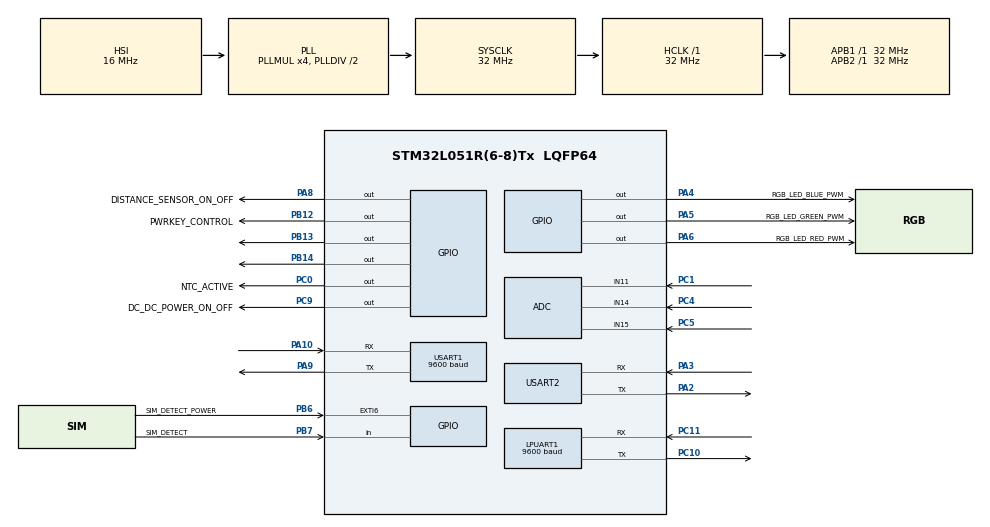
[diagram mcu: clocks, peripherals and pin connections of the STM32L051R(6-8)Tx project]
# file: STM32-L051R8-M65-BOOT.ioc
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ADC.ContinuousConvMode=ENABLE
ADC.DMAContinuousRequests=ENABLE
ADC.Overrun=ADC_OVR_DATA_OVERWRITTEN
ADC.SamplingTime=ADC_SAMPLETIME_79CYCLES_5
Dma.ADC.0.Direction=DMA_PERIPH_TO_MEMORY
Dma.ADC.0.Instance=DMA1_Channel1
Dma.ADC.0.MemDataAlignment=DMA_MDATAALIGN_HALFWORD
Dma.ADC.0.MemInc=DMA_MINC_ENABLE
Dma.ADC.0.Mode=DMA_CIRCULAR
Dma.ADC.0.PeriphDataAlignment=DMA_PDATAALIGN_HALFWORD
Dma.ADC.0.PeriphInc=DMA_PINC_DISABLE
Dma.ADC.0.Priority=DMA_PRIORITY_LOW
Dma.Request0=ADC
LPUART1.BaudRate=9600
LPUART1.WordLength=UART_WORDLENGTH_8B
Mcu.Family=STM32L0
Mcu.Name=STM32L051R(6-8)Tx
Mcu.Package=LQFP64
NVIC.ADC1_COMP_IRQn=true\:1\:0\:true\:false\:true\:true\:true\:true
NVIC.DMA1_Channel1_IRQn=true\:1\:0\:true\:false\:true\:false\:true\:true
NVIC.RCC_IRQn=true\:0\:0\:false\:false\:true\:true\:false\:true
NVIC.USART1_IRQn=true\:0\:0\:false\:false\:true\:true\:true\:true
NVIC.USART2_IRQn=true\:0\:0\:false\:false\:true\:true\:true\:true
PA10.Mode=Asynchronous
PA10.Signal=USART1_RX
PA13.Mode=Serial_Wire
PA13.Signal=SYS_SWDIO
PA14.Mode=Serial_Wire
PA14.Signal=SYS_SWCLK
PA2.Mode=Asynchronous
PA2.Signal=USART2_TX
PA3.Mode=Asynchronous
PA3.Signal=USART2_RX
PA4.GPIO_Label=RGB_LED_BLUE_PWM
PA4.GPIO_Speed=GPIO_SPEED_FREQ_VERY_HIGH
PA4.Signal=GPIO_Output
PA5.GPIO_Label=RGB_LED_GREEN_PWM
PA5.GPIO_Speed=GPIO_SPEED_FREQ_VERY_HIGH
PA5.Signal=GPIO_Output
PA6.GPIO_Label=RGB_LED_RED_PWM
PA6.GPIO_Speed=GPIO_SPEED_FREQ_VERY_HIGH
PA6.Signal=GPIO_Output
PA8.GPIO_Label=DISTANCE_SENSOR_ON_OFF
PA8.Signal=GPIO_Output
PA9.Mode=Asynchronous
PA9.Signal=USART1_TX
PB12.GPIO_Label=PWRKEY_CONTROL
PB12.Signal=GPIO_Output
PB13.Signal=GPIO_Output
PB14.Signal=GPIO_Output
PB6.GPIO_Label=SIM_DETECT_POWER
PB6.Signal=GPXTI6
PB7.GPIO_Label=SIM_DETECT
PB7.Signal=GPIO_Input
PC0.GPIO_Label=NTC_ACTIVE
PC0.Signal=GPIO_Output
PC1.Mode=IN11
PC1.Signal=ADC_IN11
PC10.Mode=Asynchronous
PC10.Signal=LPUART1_TX
PC11.Mode=Asynchronous
PC11.Signal=LPUART1_RX
PC14-OSC32_IN.Mode=LSE-External-Oscillator
PC14-OSC32_IN.Signal=RCC_OSC32_IN
PC15-OSC32_OUT.Mode=LSE-External-Oscillator
PC15-OSC32_OUT.Signal=RCC_OSC32_OUT
PC4.Mode=IN14
PC4.Signal=ADC_IN14
PC5.Mode=IN15
PC5.Signal=ADC_IN15
PC9.GPIO_Label=DC_DC_POWER_ON_OFF
PC9.Signal=GPIO_Output
PH0-OSC_IN.Mode=HSE-External-Oscillator
PH0-OSC_IN.Signal=RCC_OSC_IN
PH1-OSC_OUT.Mode=HSE-External-Oscillator
PH1-OSC_OUT.Signal=RCC_OSC_OUT
ProjectManager.HeapSize=0x200
ProjectManager.StackSize=0x400
ProjectManager.TargetToolchain=EWARM V7
RCC.AHBFreq_Value=32000000
RCC.APB1Freq_Value=32000000
RCC.APB1TimFreq_Value=32000000
RCC.APB2Freq_Value=32000000
RCC.APB2TimFreq_Value=32000000
RCC.HCLKFreq_Value=32000000
RCC.HSE_VALUE=8000000
RCC.HSI16_VALUE=16000000
RCC.HSI_VALUE=16000000
RCC.MSI_VALUE=2097000
RCC.PLLMUL=RCC_PLLMUL_4
RCC.SYSCLKFreq_VALUE=32000000
RCC.SYSCLKSource=RCC_SYSCLKSOURCE_PLLCLK
RCC.VCOOutputFreq_Value=64000000
RTC.Date=21
RTC.Month=RTC_MONTH_AUGUST
RTC.Year=23
USART1.BaudRate=9600
USART1.VirtualMode-Asynchronous=VM_ASYNC
USART2.VirtualMode-Asynchronous=VM_ASYNC
VP_ADC_Vref_Input.Mode=IN-Vrefint
VP_RTC_VS_RTC_Activate.Mode=RTC_Enabled
VP_RTC_VS_RTC_Calendar.Mode=RTC_Calendar
board=custom

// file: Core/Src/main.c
/* USER CODE BEGIN Header */
/**
 ******************************************************************************
 * @file           : main.c
 * @brief          : Main program body
 ******************************************************************************
 * @attention
 *
 * Copyright (c) 2023 STMicroelectronics.
 * All rights reserved.
 *
 * This software is licensed under terms that can be found in the LICENSE file
 * in the root directory of this software component.
 * If no LICENSE file comes with this software, it is provided AS-IS.
 *
 ******************************************************************************
 */
/* USER CODE END Header */
#include "main.h"
#include "adc.h"
#include "dma.h"
#include "usart.h"
#include "rtc.h"
#include "gpio.h"

/* USER CODE BEGIN Includes */
#include "usr_general.h"

/* USER CODE END Includes */

/* USER CODE BEGIN PV */
_io S_FIRST_INITIAL_PARAMETERS m_sFirstInitialParameter = {
    .pPowerPort          =  GPIOC,
    .pPowerKeyPort       =  GPIOB,

    .dcPowerOnOffPin     =  GPIO_PIN_9,
    .powerKeyControlPin  =  GPIO_PIN_12,

    .pLogUart            =  &hlpuart1,
};
/* USER CODE END PV */

void SystemClock_Config(void);

int main(void)
{

  /* MCU Configuration--------------------------------------------------------*/

  /* Reset of all peripherals, Initializes the Flash interface and the Systick. */
  HAL_Init();

  /* Configure the system clock */
  SystemClock_Config();

  /* Initialize all configured peripherals */
  MX_GPIO_Init();
  MX_DMA_Init();
  MX_USART1_UART_Init();
  MX_RTC_Init();
  MX_LPUART1_UART_Init();
  MX_USART2_UART_Init();
  MX_ADC_Init();
  /* USER CODE BEGIN 2 */
  UsrSystemInitial(&m_sFirstInitialParameter);
  /* USER CODE END 2 */

  /* Infinite loop */
  while (1)
  {

    /* USER CODE BEGIN 3 */
    UsrSystemGeneral();
  }
  /* USER CODE END 3 */
}

void SystemClock_Config(void)
{
  RCC_OscInitTypeDef RCC_OscInitStruct = {0};
  RCC_ClkInitTypeDef RCC_ClkInitStruct = {0};
  RCC_PeriphCLKInitTypeDef PeriphClkInit = {0};

  /** Configure the main internal regulator output voltage
  */
  __HAL_PWR_VOLTAGESCALING_CONFIG(PWR_REGULATOR_VOLTAGE_SCALE1);

  /** Initializes the RCC Oscillators according to the specified parameters
  * in the RCC_OscInitTypeDef structure.
  */
  RCC_OscInitStruct.OscillatorType = RCC_OSCILLATORTYPE_HSI|RCC_OSCILLATORTYPE_LSI;
  RCC_OscInitStruct.HSIState = RCC_HSI_ON;
  RCC_OscInitStruct.HSICalibrationValue = RCC_HSICALIBRATION_DEFAULT;
  RCC_OscInitStruct.LSIState = RCC_LSI_ON;
  RCC_OscInitStruct.PLL.PLLState = RCC_PLL_ON;
  RCC_OscInitStruct.PLL.PLLSource = RCC_PLLSOURCE_HSI;
  RCC_OscInitStruct.PLL.PLLMUL = RCC_PLLMUL_4;
  RCC_OscInitStruct.PLL.PLLDIV = RCC_PLLDIV_2;
  if (HAL_RCC_OscConfig(&RCC_OscInitStruct) != HAL_OK)
  {
    Error_Handler();
  }

  /** Initializes the CPU, AHB and APB buses clocks
  */
  RCC_ClkInitStruct.ClockType = RCC_CLOCKTYPE_HCLK|RCC_CLOCKTYPE_SYSCLK
                              |RCC_CLOCKTYPE_PCLK1|RCC_CLOCKTYPE_PCLK2;
  RCC_ClkInitStruct.SYSCLKSource = RCC_SYSCLKSOURCE_PLLCLK;
  RCC_ClkInitStruct.AHBCLKDivider = RCC_SYSCLK_DIV1;
  RCC_ClkInitStruct.APB1CLKDivider = RCC_HCLK_DIV1;
  RCC_ClkInitStruct.APB2CLKDivider = RCC_HCLK_DIV1;

  if (HAL_RCC_ClockConfig(&RCC_ClkInitStruct, FLASH_LATENCY_1) != HAL_OK)
  {
    Error_Handler();
  }
  PeriphClkInit.PeriphClockSelection = RCC_PERIPHCLK_USART1|RCC_PERIPHCLK_USART2
                              |RCC_PERIPHCLK_LPUART1|RCC_PERIPHCLK_RTC;
  PeriphClkInit.Usart1ClockSelection = RCC_USART1CLKSOURCE_PCLK2;
  PeriphClkInit.Usart2ClockSelection = RCC_USART2CLKSOURCE_PCLK1;
  PeriphClkInit.Lpuart1ClockSelection = RCC_LPUART1CLKSOURCE_PCLK1;
  PeriphClkInit.RTCClockSelection = RCC_RTCCLKSOURCE_LSI;
  if (HAL_RCCEx_PeriphCLKConfig(&PeriphClkInit) != HAL_OK)
  {
    Error_Handler();
  }
}

void Error_Handler(void)
{
  __disable_irq();
  while (1)
  {
  }
}
